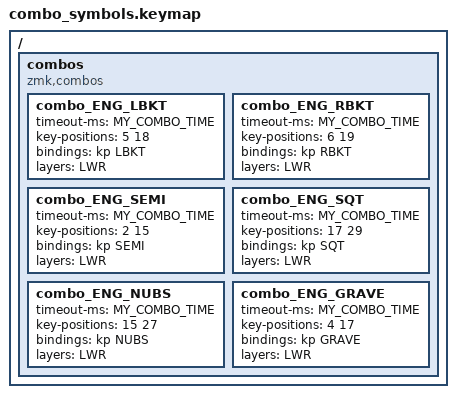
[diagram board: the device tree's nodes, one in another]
/ {
    combos {
        compatible = "zmk,combos";
        combo_ENG_LBKT {
            timeout-ms = <MY_COMBO_TIME>;
            key-positions = <5 18>;
            bindings = <&kp LBKT>;
            layers = <LWR>;
        };
        combo_ENG_RBKT {
            timeout-ms = <MY_COMBO_TIME>;
            key-positions = <6 19>;
            bindings = <&kp RBKT>;
            layers = <LWR>;
        };
        combo_ENG_SEMI {
            timeout-ms = <MY_COMBO_TIME>;
            key-positions = <2 15>;
            bindings = <&kp SEMI>;
            layers = <LWR>;
        };
        combo_ENG_SQT {
            timeout-ms = <MY_COMBO_TIME>;
            key-positions = <17 29>;
            bindings = <&kp SQT>;
            layers = <LWR>;
        };
        combo_ENG_NUBS {
            timeout-ms = <MY_COMBO_TIME>;
            key-positions = <15 27>;
            bindings = <&kp NUBS>;
            layers = <LWR>;
        };
        combo_ENG_GRAVE {
            timeout-ms = <MY_COMBO_TIME>;
            key-positions = <4 17>;
            bindings = <&kp GRAVE>;
            layers = <LWR>;
        };
    };
};
